# N32H7xx register map
Vendor: Nationstech Ltd.; File version: 1.0
CPU: CM7 r1p1, little endian, MPU, FPU, 4 interrupt priority bits
Registers are 32-bit, read-write, reset 0x0 unless marked. A register's access mark holds for its fields unless they carry their own. Offsets are from the block's base; [hi:lo] are bit positions; {n}, {i} and the like mark numbered series.

## RCC — Reset and clock control
Base 0x58030000
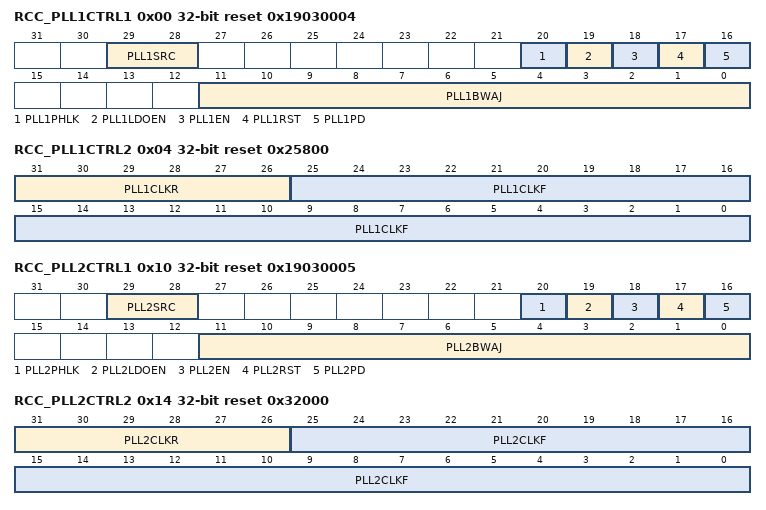
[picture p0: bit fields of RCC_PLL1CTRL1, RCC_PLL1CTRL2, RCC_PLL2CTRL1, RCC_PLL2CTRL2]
0x00 RCC_PLL1CTRL1 reset 0x19030004 — nan
  [29:28] PLL1SRC, [20] PLL1PHLK ro, [19] PLL1LDOEN, [18] PLL1EN, [17] PLL1RST, [16] PLL1PD, [11:0] PLL1BWAJ
0x04 RCC_PLL1CTRL2 reset 0x25800 — nan
  [31:26] PLL1CLKR, [25:0] PLL1CLKF
0x10 RCC_PLL2CTRL1 reset 0x19030005 — nan
  [29:28] PLL2SRC, [20] PLL2PHLK ro, [19] PLL2LDOEN, [18] PLL2EN, [17] PLL2RST, [16] PLL2PD, [11:0] PLL2BWAJ
0x14 RCC_PLL2CTRL2 reset 0x32000 — nan
  [31:26] PLL2CLKR, [25:0] PLL2CLKF
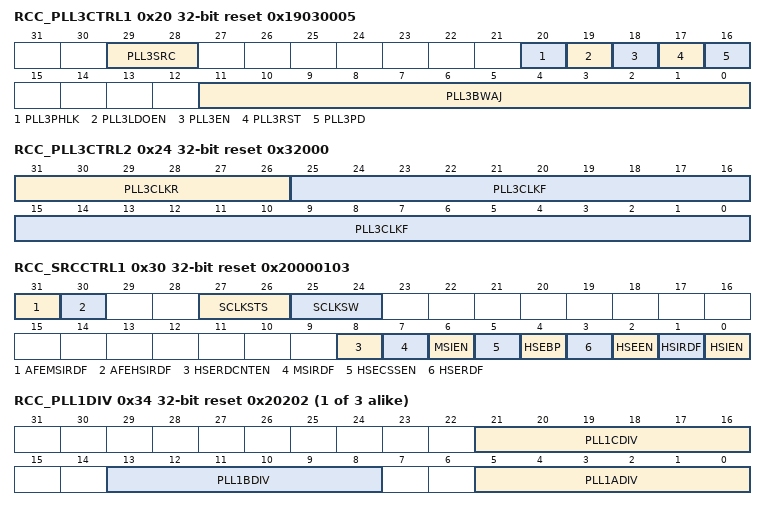
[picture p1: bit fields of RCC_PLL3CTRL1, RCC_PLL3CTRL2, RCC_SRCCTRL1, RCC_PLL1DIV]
0x20 RCC_PLL3CTRL1 reset 0x19030005 — nan
  [29:28] PLL3SRC, [20] PLL3PHLK ro, [19] PLL3LDOEN, [18] PLL3EN, [17] PLL3RST, [16] PLL3PD, [11:0] PLL3BWAJ
0x24 RCC_PLL3CTRL2 reset 0x32000 — nan
  [31:26] PLL3CLKR, [25:0] PLL3CLKF
0x30 RCC_SRCCTRL1 reset 0x20000103 — nan
  [31] AFEMSIRDF ro, [30] AFEHSIRDF ro, [27:26] SCLKSTS ro, [25:24] SCLKSW, [8] HSERDCNTEN, [7] MSIRDF ro, [6] MSIEN, [5] HSECSSEN, [4] HSEBP, [3] HSERDF ro, [2] HSEEN, [1] HSIRDF ro, [0] HSIEN
{0x30+4i} RCC_PLL{i}DIV reset 0x20202 (i=1..3) — nan
  [21:16] PLL{i}CDIV, [13:8] PLL{i}BDIV, [5:0] PLL{i}ADIV
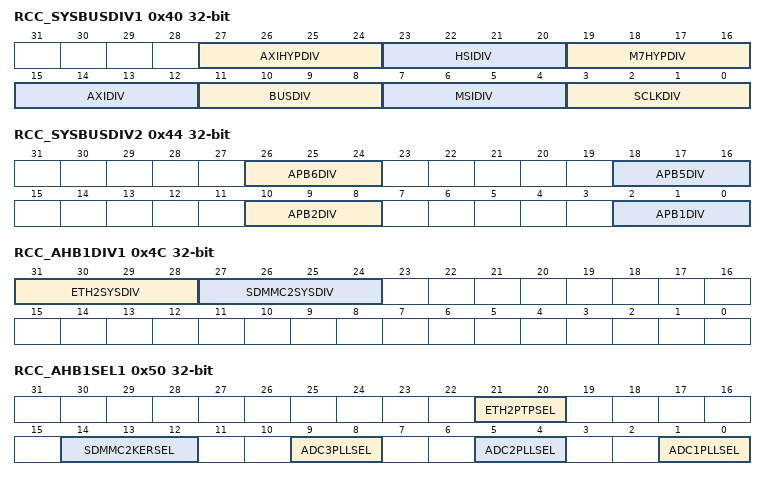
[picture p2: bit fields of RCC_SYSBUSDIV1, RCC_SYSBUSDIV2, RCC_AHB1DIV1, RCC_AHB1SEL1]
0x40 RCC_SYSBUSDIV1 — nan
  [27:24] AXIHYPDIV, [23:20] HSIDIV, [19:16] M7HYPDIV, [15:12] AXIDIV, [11:8] BUSDIV, [7:4] MSIDIV, [3:0] SCLKDIV
0x44 RCC_SYSBUSDIV2 — nan
  [26:24] APB6DIV, [18:16] APB5DIV, [10:8] APB2DIV, [2:0] APB1DIV
0x48 RCC_BOOTMODE — nan
  [31:0] MODE
0x4C RCC_AHB1DIV1 — nan
  [31:28] ETH2SYSDIV, [27:24] SDMMC2SYSDIV
0x50 RCC_AHB1SEL1 — nan
  [21:20] ETH2PTPSEL, [14:12] SDMMC2KERSEL, [9:8] ADC3PLLSEL, [5:4] ADC2PLLSEL, [1:0] ADC1PLLSEL
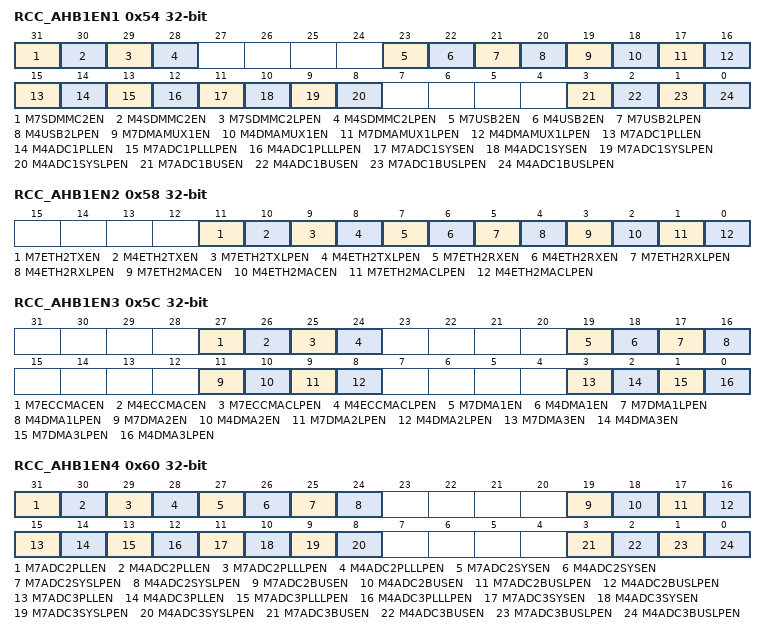
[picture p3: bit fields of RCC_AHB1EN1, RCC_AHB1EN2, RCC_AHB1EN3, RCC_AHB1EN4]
0x54 RCC_AHB1EN1 — nan
  [31] M7SDMMC2EN, [30] M4SDMMC2EN, [29] M7SDMMC2LPEN, [28] M4SDMMC2LPEN, [23] M7USB2EN, [22] M4USB2EN, [21] M7USB2LPEN, [20] M4USB2LPEN, [19] M7DMAMUX1EN, [18] M4DMAMUX1EN, [17] M7DMAMUX1LPEN, [16] M4DMAMUX1LPEN, [15] M7ADC1PLLEN, [14] M4ADC1PLLEN, [13] M7ADC1PLLLPEN, [12] M4ADC1PLLLPEN, [11] M7ADC1SYSEN, [10] M4ADC1SYSEN, [9] M7ADC1SYSLPEN, [8] M4ADC1SYSLPEN, [3] M7ADC1BUSEN, [2] M4ADC1BUSEN, [1] M7ADC1BUSLPEN, [0] M4ADC1BUSLPEN
0x58 RCC_AHB1EN2 — nan
  [11] M7ETH2TXEN, [10] M4ETH2TXEN, [9] M7ETH2TXLPEN, [8] M4ETH2TXLPEN, [7] M7ETH2RXEN, [6] M4ETH2RXEN, [5] M7ETH2RXLPEN, [4] M4ETH2RXLPEN, [3] M7ETH2MACEN, [2] M4ETH2MACEN, [1] M7ETH2MACLPEN, [0] M4ETH2MACLPEN
0x5C RCC_AHB1EN3 — nan
  [27] M7ECCMACEN, [26] M4ECCMACEN, [25] M7ECCMACLPEN, [24] M4ECCMACLPEN, [19] M7DMA1EN, [18] M4DMA1EN, [17] M7DMA1LPEN, [16] M4DMA1LPEN, [11] M7DMA2EN, [10] M4DMA2EN, [9] M7DMA2LPEN, [8] M4DMA2LPEN, [3] M7DMA3EN, [2] M4DMA3EN, [1] M7DMA3LPEN, [0] M4DMA3LPEN
0x60 RCC_AHB1EN4 — nan
  [31] M7ADC2PLLEN, [30] M4ADC2PLLEN, [29] M7ADC2PLLLPEN, [28] M4ADC2PLLLPEN, [27] M7ADC2SYSEN, [26] M4ADC2SYSEN, [25] M7ADC2SYSLPEN, [24] M4ADC2SYSLPEN, [19] M7ADC2BUSEN, [18] M4ADC2BUSEN, [17] M7ADC2BUSLPEN, [16] M4ADC2BUSLPEN, [15] M7ADC3PLLEN, [14] M4ADC3PLLEN, [13] M7ADC3PLLLPEN, [12] M4ADC3PLLLPEN, [11] M7ADC3SYSEN, [10] M4ADC3SYSEN, [9] M7ADC3SYSLPEN, [8] M4ADC3SYSLPEN, [3] M7ADC3BUSEN, [2] M4ADC3BUSEN, [1] M7ADC3BUSLPEN, [0] M4ADC3BUSLPEN
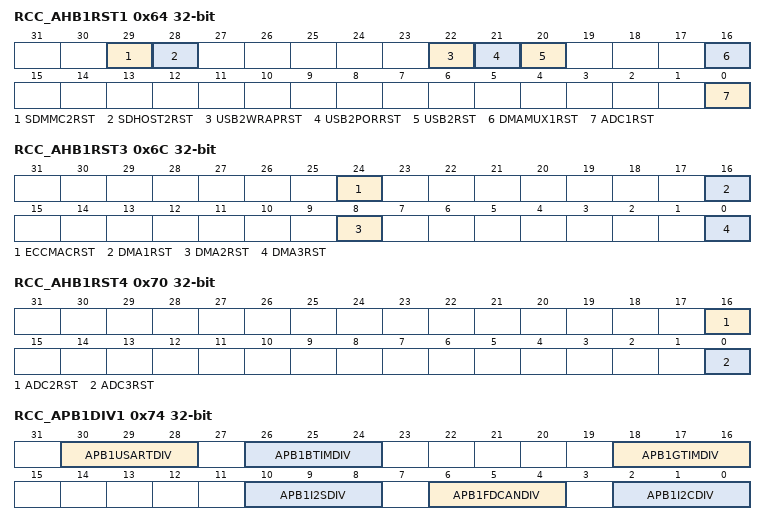
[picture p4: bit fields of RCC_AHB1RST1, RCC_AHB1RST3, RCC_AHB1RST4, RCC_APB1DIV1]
0x64 RCC_AHB1RST1 — nan
  [29] SDMMC2RST, [28] SDHOST2RST, [22] USB2WRAPRST, [21] USB2PORRST, [20] USB2RST, [16] DMAMUX1RST, [0] ADC1RST
0x68 RCC_AHB1RST2 — nan
  [0] ETH2RST
0x6C RCC_AHB1RST3 — nan
  [24] ECCMACRST, [16] DMA1RST, [8] DMA2RST, [0] DMA3RST
0x70 RCC_AHB1RST4 — nan
  [16] ADC2RST, [0] ADC3RST
0x74 RCC_APB1DIV1 — nan
  [30:28] APB1USARTDIV, [26:24] APB1BTIMDIV, [18:16] APB1GTIMDIV, [10:8] APB1I2SDIV, [6:4] APB1FDCANDIV, [2:0] APB1I2CDIV
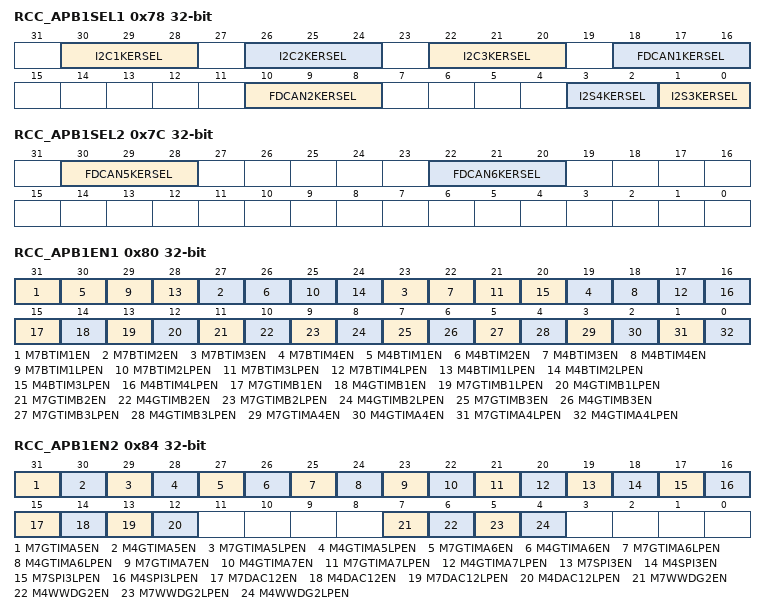
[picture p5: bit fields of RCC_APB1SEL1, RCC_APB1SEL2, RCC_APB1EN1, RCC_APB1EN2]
0x78 RCC_APB1SEL1 — nan
  [30:28] I2C1KERSEL, [26:24] I2C2KERSEL, [22:20] I2C3KERSEL, [18:16] FDCAN1KERSEL, [10:8] FDCAN2KERSEL, [3:2] I2S4KERSEL, [1:0] I2S3KERSEL
0x7C RCC_APB1SEL2 — nan
  [30:28] FDCAN5KERSEL, [22:20] FDCAN6KERSEL
0x80 RCC_APB1EN1 — nan
  [35-4n] M7BTIM{n}EN (n=1..4), [34-4n] M4BTIM{n}EN (n=1..4), [33-4n] M7BTIM{n}LPEN (n=1..4), [32-4n] M4BTIM{n}LPEN (n=1..4), [15] M7GTIMB1EN, [14] M4GTIMB1EN, [13] M7GTIMB1LPEN, [12] M4GTIMB1LPEN, [11] M7GTIMB2EN, [10] M4GTIMB2EN, [9] M7GTIMB2LPEN, [8] M4GTIMB2LPEN, [7] M7GTIMB3EN, [6] M4GTIMB3EN, [5] M7GTIMB3LPEN, [4] M4GTIMB3LPEN, [3] M7GTIMA4EN, [2] M4GTIMA4EN, [1] M7GTIMA4LPEN, [0] M4GTIMA4LPEN
0x84 RCC_APB1EN2 — nan
  [31] M7GTIMA5EN, [30] M4GTIMA5EN, [29] M7GTIMA5LPEN, [28] M4GTIMA5LPEN, [27] M7GTIMA6EN, [26] M4GTIMA6EN, [25] M7GTIMA6LPEN, [24] M4GTIMA6LPEN, [23] M7GTIMA7EN, [22] M4GTIMA7EN, [21] M7GTIMA7LPEN, [20] M4GTIMA7LPEN, [19] M7SPI3EN, [18] M4SPI3EN, [17] M7SPI3LPEN, [16] M4SPI3LPEN, [15] M7DAC12EN, [14] M4DAC12EN, [13] M7DAC12LPEN, [12] M4DAC12LPEN, [7] M7WWDG2EN, [6] M4WWDG2EN, [5] M7WWDG2LPEN, [4] M4WWDG2LPEN
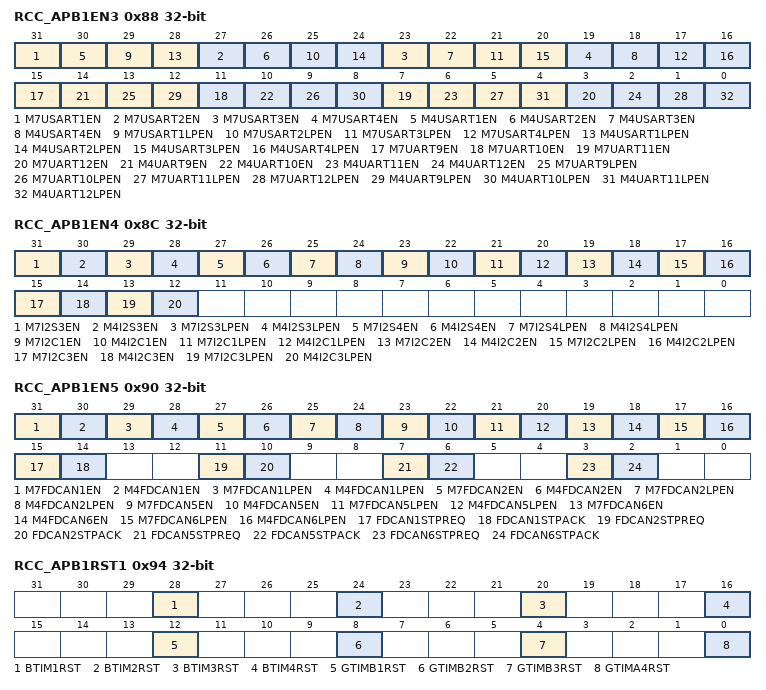
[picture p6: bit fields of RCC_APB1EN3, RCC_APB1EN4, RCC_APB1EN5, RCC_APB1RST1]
0x88 RCC_APB1EN3 — nan
  [35-4n] M7USART{n}EN (n=1..4), [34-4n] M4USART{n}EN (n=1..4), [33-4n] M7USART{n}LPEN (n=1..4), [32-4n] M4USART{n}LPEN (n=1..4), [51-4n] M7UART{n}EN (n=9..12), [50-4n] M4UART{n}EN (n=9..12), [49-4n] M7UART{n}LPEN (n=9..12), [48-4n] M4UART{n}LPEN (n=9..12)
0x8C RCC_APB1EN4 — nan
  [31] M7I2S3EN, [30] M4I2S3EN, [29] M7I2S3LPEN, [28] M4I2S3LPEN, [27] M7I2S4EN, [26] M4I2S4EN, [25] M7I2S4LPEN, [24] M4I2S4LPEN, [23] M7I2C1EN, [22] M4I2C1EN, [21] M7I2C1LPEN, [20] M4I2C1LPEN, [19] M7I2C2EN, [18] M4I2C2EN, [17] M7I2C2LPEN, [16] M4I2C2LPEN, [15] M7I2C3EN, [14] M4I2C3EN, [13] M7I2C3LPEN, [12] M4I2C3LPEN
0x90 RCC_APB1EN5 — nan
  [31] M7FDCAN1EN, [30] M4FDCAN1EN, [29] M7FDCAN1LPEN, [28] M4FDCAN1LPEN, [27] M7FDCAN2EN, [26] M4FDCAN2EN, [25] M7FDCAN2LPEN, [24] M4FDCAN2LPEN, [23] M7FDCAN5EN, [22] M4FDCAN5EN, [21] M7FDCAN5LPEN, [20] M4FDCAN5LPEN, [19] M7FDCAN6EN, [18] M4FDCAN6EN, [17] M7FDCAN6LPEN, [16] M4FDCAN6LPEN, [15] FDCAN1STPREQ, [14] FDCAN1STPACK ro, [11] FDCAN2STPREQ, [10] FDCAN2STPACK ro, [7] FDCAN5STPREQ, [6] FDCAN5STPACK ro, [3] FDCAN6STPREQ, [2] FDCAN6STPACK ro
0x94 RCC_APB1RST1 — nan
  [32-4n] BTIM{n}RST (n=1..4), [12] GTIMB1RST, [8] GTIMB2RST, [4] GTIMB3RST, [0] GTIMA4RST
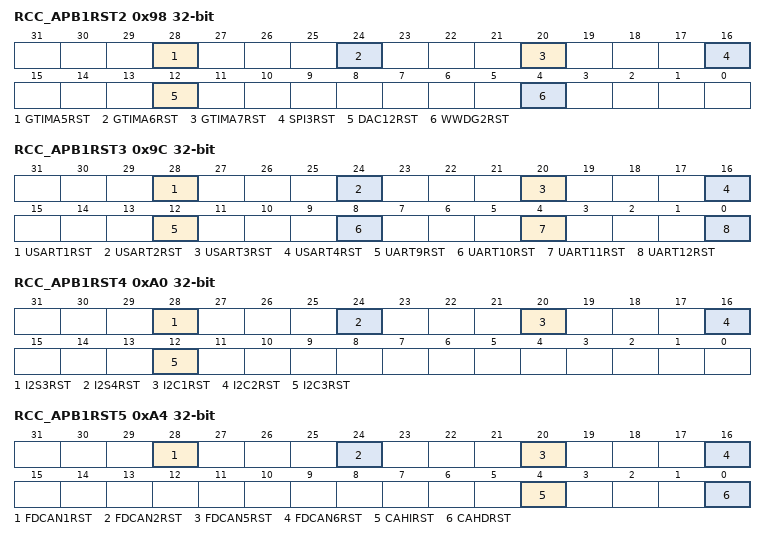
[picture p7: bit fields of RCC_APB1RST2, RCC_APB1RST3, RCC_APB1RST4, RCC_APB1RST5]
0x98 RCC_APB1RST2 — nan
  [28] GTIMA5RST, [24] GTIMA6RST, [20] GTIMA7RST, [16] SPI3RST, [12] DAC12RST, [4] WWDG2RST
0x9C RCC_APB1RST3 — nan
  [32-4n] USART{n}RST (n=1..4), [48-4n] UART{n}RST (n=9..12)
0xA0 RCC_APB1RST4 — nan
  [28] I2S3RST, [24] I2S4RST, [20] I2C1RST, [16] I2C2RST, [12] I2C3RST
0xA4 RCC_APB1RST5 — nan
  [28] FDCAN1RST, [24] FDCAN2RST, [20] FDCAN5RST, [16] FDCAN6RST, [4] CAHIRST, [0] CAHDRST
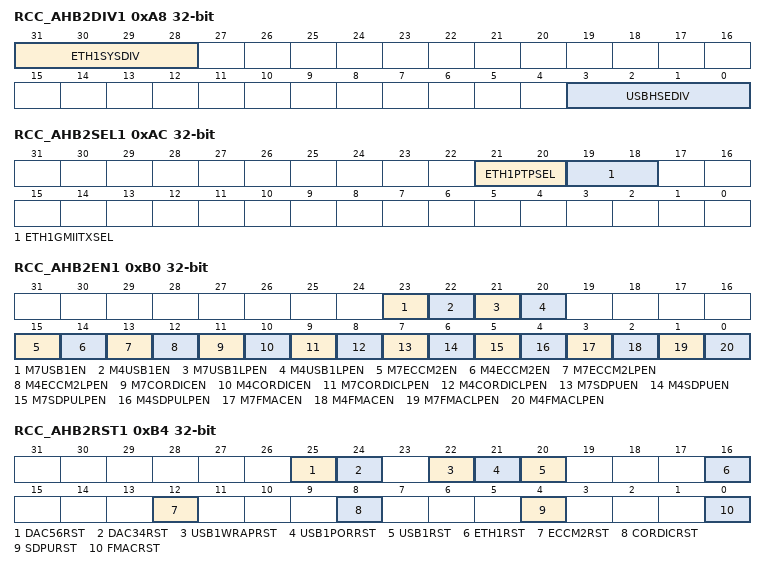
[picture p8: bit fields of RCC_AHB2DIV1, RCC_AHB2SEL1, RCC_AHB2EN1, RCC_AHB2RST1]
0xA8 RCC_AHB2DIV1 — nan
  [31:28] ETH1SYSDIV, [3:0] USBHSEDIV
0xAC RCC_AHB2SEL1 — nan
  [21:20] ETH1PTPSEL, [19:18] ETH1GMIITXSEL
0xB0 RCC_AHB2EN1 — nan
  [23] M7USB1EN, [22] M4USB1EN, [21] M7USB1LPEN, [20] M4USB1LPEN, [15] M7ECCM2EN, [14] M4ECCM2EN, [13] M7ECCM2LPEN, [12] M4ECCM2LPEN, [11] M7CORDICEN, [10] M4CORDICEN, [9] M7CORDICLPEN, [8] M4CORDICLPEN, [7] M7SDPUEN, [6] M4SDPUEN, [5] M7SDPULPEN, [4] M4SDPULPEN, [3] M7FMACEN, [2] M4FMACEN, [1] M7FMACLPEN, [0] M4FMACLPEN
0xB4 RCC_AHB2RST1 — nan
  [25] DAC56RST, [24] DAC34RST, [22] USB1WRAPRST, [21] USB1PORRST, [20] USB1RST, [16] ETH1RST, [12] ECCM2RST, [8] CORDICRST, [4] SDPURST, [0] FMACRST
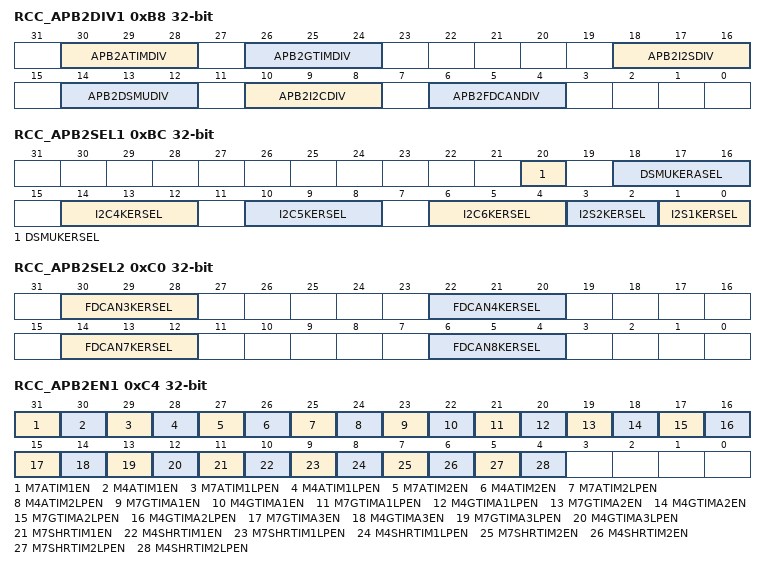
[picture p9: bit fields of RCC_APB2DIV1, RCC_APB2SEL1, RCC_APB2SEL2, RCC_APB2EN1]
0xB8 RCC_APB2DIV1 — nan
  [30:28] APB2ATIMDIV, [26:24] APB2GTIMDIV, [18:16] APB2I2SDIV, [14:12] APB2DSMUDIV, [10:8] APB2I2CDIV, [6:4] APB2FDCANDIV
0xBC RCC_APB2SEL1 — nan
  [20] DSMUKERSEL, [18:16] DSMUKERASEL, [14:12] I2C4KERSEL, [10:8] I2C5KERSEL, [6:4] I2C6KERSEL, [3:2] I2S2KERSEL, [1:0] I2S1KERSEL
0xC0 RCC_APB2SEL2 — nan
  [30:28] FDCAN3KERSEL, [22:20] FDCAN4KERSEL, [14:12] FDCAN7KERSEL, [6:4] FDCAN8KERSEL
0xC4 RCC_APB2EN1 — nan
  [31] M7ATIM1EN, [30] M4ATIM1EN, [29] M7ATIM1LPEN, [28] M4ATIM1LPEN, [27] M7ATIM2EN, [26] M4ATIM2EN, [25] M7ATIM2LPEN, [24] M4ATIM2LPEN, [23] M7GTIMA1EN, [22] M4GTIMA1EN, [21] M7GTIMA1LPEN, [20] M4GTIMA1LPEN, [19] M7GTIMA2EN, [18] M4GTIMA2EN, [17] M7GTIMA2LPEN, [16] M4GTIMA2LPEN, [15] M7GTIMA3EN, [14] M4GTIMA3EN, [13] M7GTIMA3LPEN, [12] M4GTIMA3LPEN, [11] M7SHRTIM1EN, [10] M4SHRTIM1EN, [9] M7SHRTIM1LPEN, [8] M4SHRTIM1LPEN, [7] M7SHRTIM2EN, [6] M4SHRTIM2EN, [5] M7SHRTIM2LPEN, [4] M4SHRTIM2LPEN
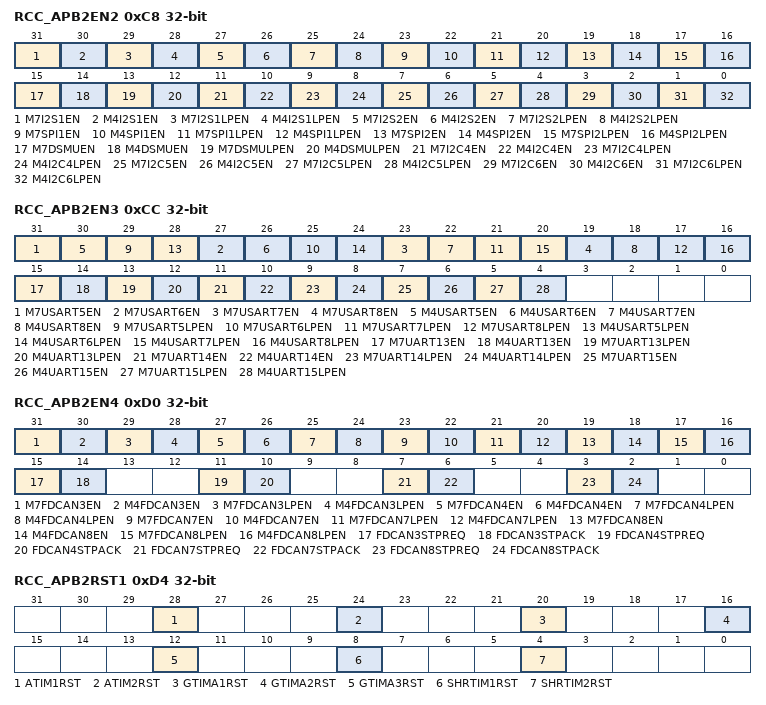
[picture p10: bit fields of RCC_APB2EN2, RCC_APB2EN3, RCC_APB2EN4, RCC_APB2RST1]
0xC8 RCC_APB2EN2 — nan
  [31] M7I2S1EN, [30] M4I2S1EN, [29] M7I2S1LPEN, [28] M4I2S1LPEN, [27] M7I2S2EN, [26] M4I2S2EN, [25] M7I2S2LPEN, [24] M4I2S2LPEN, [23] M7SPI1EN, [22] M4SPI1EN, [21] M7SPI1LPEN, [20] M4SPI1LPEN, [19] M7SPI2EN, [18] M4SPI2EN, [17] M7SPI2LPEN, [16] M4SPI2LPEN, [15] M7DSMUEN, [14] M4DSMUEN, [13] M7DSMULPEN, [12] M4DSMULPEN, [11] M7I2C4EN, [10] M4I2C4EN, [9] M7I2C4LPEN, [8] M4I2C4LPEN, [7] M7I2C5EN, [6] M4I2C5EN, [5] M7I2C5LPEN, [4] M4I2C5LPEN, [3] M7I2C6EN, [2] M4I2C6EN, [1] M7I2C6LPEN, [0] M4I2C6LPEN
0xCC RCC_APB2EN3 — nan
  [51-4n] M7USART{n}EN (n=5..8), [50-4n] M4USART{n}EN (n=5..8), [49-4n] M7USART{n}LPEN (n=5..8), [48-4n] M4USART{n}LPEN (n=5..8), [15] M7UART13EN, [14] M4UART13EN, [13] M7UART13LPEN, [12] M4UART13LPEN, [11] M7UART14EN, [10] M4UART14EN, [9] M7UART14LPEN, [8] M4UART14LPEN, [7] M7UART15EN, [6] M4UART15EN, [5] M7UART15LPEN, [4] M4UART15LPEN
0xD0 RCC_APB2EN4 — nan
  [31] M7FDCAN3EN, [30] M4FDCAN3EN, [29] M7FDCAN3LPEN, [28] M4FDCAN3LPEN, [27] M7FDCAN4EN, [26] M4FDCAN4EN, [25] M7FDCAN4LPEN, [24] M4FDCAN4LPEN, [23] M7FDCAN7EN, [22] M4FDCAN7EN, [21] M7FDCAN7LPEN, [20] M4FDCAN7LPEN, [19] M7FDCAN8EN, [18] M4FDCAN8EN, [17] M7FDCAN8LPEN, [16] M4FDCAN8LPEN, [15] FDCAN3STPREQ, [14] FDCAN3STPACK ro, [11] FDCAN4STPREQ, [10] FDCAN4STPACK ro, [7] FDCAN7STPREQ, [6] FDCAN7STPACK ro, [3] FDCAN8STPREQ, [2] FDCAN8STPACK ro
0xD4 RCC_APB2RST1 — nan
  [28] ATIM1RST, [24] ATIM2RST, [20] GTIMA1RST, [16] GTIMA2RST, [12] GTIMA3RST, [8] SHRTIM1RST, [4] SHRTIM2RST
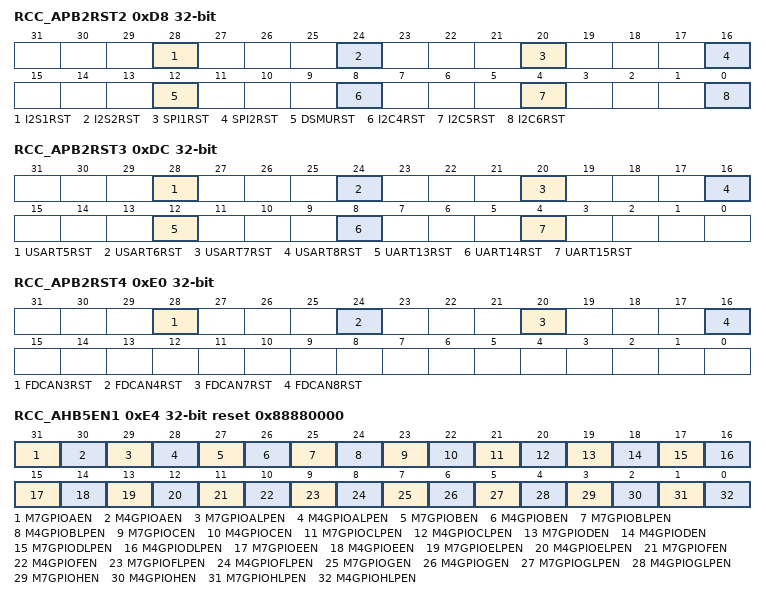
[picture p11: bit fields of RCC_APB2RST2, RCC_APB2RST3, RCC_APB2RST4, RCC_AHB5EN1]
0xD8 RCC_APB2RST2 — nan
  [28] I2S1RST, [24] I2S2RST, [20] SPI1RST, [16] SPI2RST, [12] DSMURST, [8] I2C4RST, [4] I2C5RST, [0] I2C6RST
0xDC RCC_APB2RST3 — nan
  [48-4n] USART{n}RST (n=5..8), [12] UART13RST, [8] UART14RST, [4] UART15RST
0xE0 RCC_APB2RST4 — nan
  [28] FDCAN3RST, [24] FDCAN4RST, [20] FDCAN7RST, [16] FDCAN8RST
0xE4 RCC_AHB5EN1 reset 0x88880000 — nan
  [31] M7GPIOAEN, [30] M4GPIOAEN, [29] M7GPIOALPEN, [28] M4GPIOALPEN, [27] M7GPIOBEN, [26] M4GPIOBEN, [25] M7GPIOBLPEN, [24] M4GPIOBLPEN, [23] M7GPIOCEN, [22] M4GPIOCEN, [21] M7GPIOCLPEN, [20] M4GPIOCLPEN, [19] M7GPIODEN, [18] M4GPIODEN, [17] M7GPIODLPEN, [16] M4GPIODLPEN, [15] M7GPIOEEN, [14] M4GPIOEEN, [13] M7GPIOELPEN, [12] M4GPIOELPEN, [11] M7GPIOFEN, [10] M4GPIOFEN, [9] M7GPIOFLPEN, [8] M4GPIOFLPEN, [7] M7GPIOGEN, [6] M4GPIOGEN, [5] M7GPIOGLPEN, [4] M4GPIOGLPEN, [3] M7GPIOHEN, [2] M4GPIOHEN, [1] M7GPIOHLPEN, [0] M4GPIOHLPEN
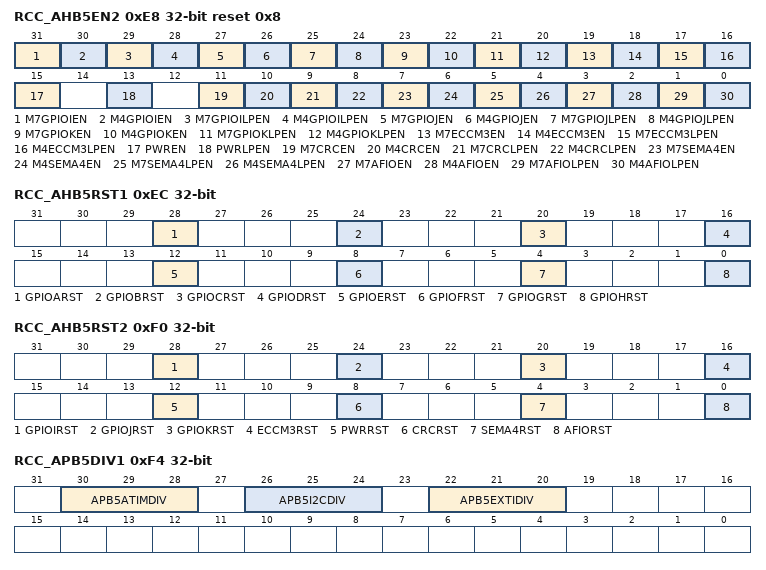
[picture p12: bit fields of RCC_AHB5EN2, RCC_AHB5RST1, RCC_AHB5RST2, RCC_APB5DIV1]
0xE8 RCC_AHB5EN2 reset 0x8 — nan
  [31] M7GPIOIEN, [30] M4GPIOIEN, [29] M7GPIOILPEN, [28] M4GPIOILPEN, [27] M7GPIOJEN, [26] M4GPIOJEN, [25] M7GPIOJLPEN, [24] M4GPIOJLPEN, [23] M7GPIOKEN, [22] M4GPIOKEN, [21] M7GPIOKLPEN, [20] M4GPIOKLPEN, [19] M7ECCM3EN, [18] M4ECCM3EN, [17] M7ECCM3LPEN, [16] M4ECCM3LPEN, [15] PWREN, [13] PWRLPEN, [11] M7CRCEN, [10] M4CRCEN, [9] M7CRCLPEN, [8] M4CRCLPEN, [7] M7SEMA4EN, [6] M4SEMA4EN, [5] M7SEMA4LPEN, [4] M4SEMA4LPEN, [3] M7AFIOEN, [2] M4AFIOEN, [1] M7AFIOLPEN, [0] M4AFIOLPEN
0xEC RCC_AHB5RST1 — nan
  [28] GPIOARST, [24] GPIOBRST, [20] GPIOCRST, [16] GPIODRST, [12] GPIOERST, [8] GPIOFRST, [4] GPIOGRST, [0] GPIOHRST
0xF0 RCC_AHB5RST2 — nan
  [28] GPIOIRST, [24] GPIOJRST, [20] GPIOKRST, [16] ECCM3RST, [12] PWRRST, [8] CRCRST, [4] SEMA4RST, [0] AFIORST
0xF4 RCC_APB5DIV1 — nan
  [30:28] APB5ATIMDIV, [26:24] APB5I2CDIV, [22:20] APB5EXTIDIV
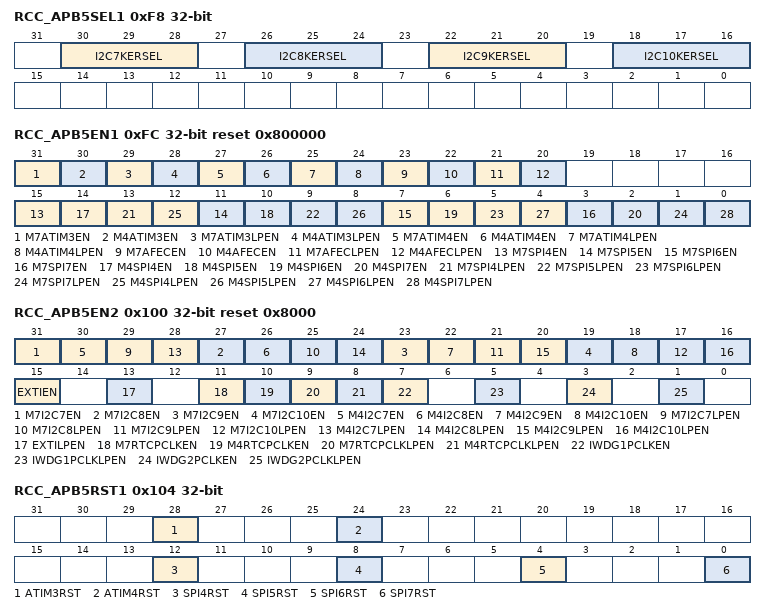
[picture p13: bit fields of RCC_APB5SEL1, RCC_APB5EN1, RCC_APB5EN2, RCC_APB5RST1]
0xF8 RCC_APB5SEL1 — nan
  [58-4n:56-4n] I2C{n}KERSEL (n=7..10)
0xFC RCC_APB5EN1 reset 0x800000 — nan
  [31] M7ATIM3EN, [30] M4ATIM3EN, [29] M7ATIM3LPEN, [28] M4ATIM3LPEN, [27] M7ATIM4EN, [26] M4ATIM4EN, [25] M7ATIM4LPEN, [24] M4ATIM4LPEN, [23] M7AFECEN, [22] M4AFECEN, [21] M7AFECLPEN, [20] M4AFECLPEN, [31-4n] M7SPI{n}EN (n=4..7), [30-4n] M4SPI{n}EN (n=4..7), [29-4n] M7SPI{n}LPEN (n=4..7), [28-4n] M4SPI{n}LPEN (n=4..7)
0x100 RCC_APB5EN2 reset 0x8000 — nan
  [59-4n] M7I2C{n}EN (n=7..10), [58-4n] M4I2C{n}EN (n=7..10), [57-4n] M7I2C{n}LPEN (n=7..10), [56-4n] M4I2C{n}LPEN (n=7..10), [15] EXTIEN, [13] EXTILPEN, [11] M7RTCPCLKEN, [10] M4RTCPCLKEN, [9] M7RTCPCLKLPEN, [8] M4RTCPCLKLPEN, [7] IWDG1PCLKEN, [5] IWDG1PCLKLPEN, [3] IWDG2PCLKEN, [1] IWDG2PCLKLPEN
0x104 RCC_APB5RST1 — nan
  [28] ATIM3RST, [24] ATIM4RST, [28-4n] SPI{n}RST (n=4..7)
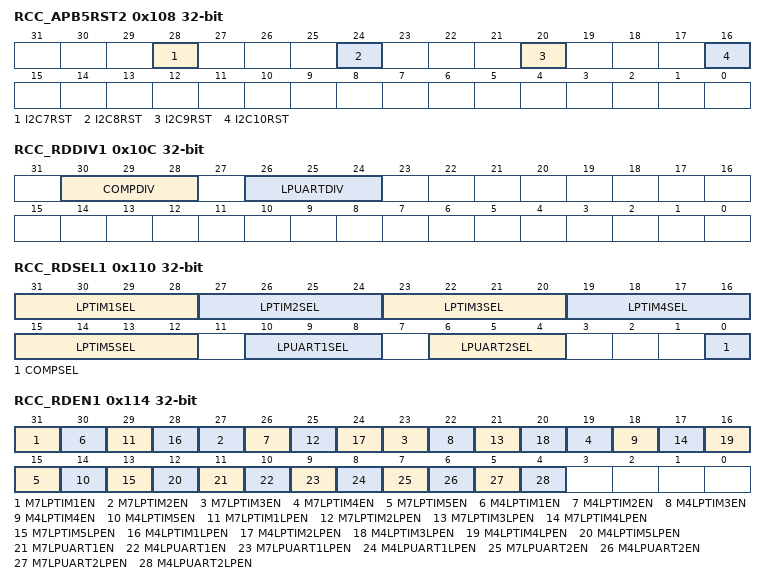
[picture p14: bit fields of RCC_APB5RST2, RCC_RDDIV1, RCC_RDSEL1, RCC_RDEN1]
0x108 RCC_APB5RST2 — nan
  [56-4n] I2C{n}RST (n=7..10)
0x10C RCC_RDDIV1 — nan
  [30:28] COMPDIV, [26:24] LPUARTDIV
0x110 RCC_RDSEL1 — nan
  [35-4n:32-4n] LPTIM{n}SEL (n=1..5), [10:8] LPUART1SEL, [6:4] LPUART2SEL, [0] COMPSEL
0x114 RCC_RDEN1 — nan
  [35-4n] M7LPTIM{n}EN (n=1..5), [34-4n] M4LPTIM{n}EN (n=1..5), [33-4n] M7LPTIM{n}LPEN (n=1..5), [32-4n] M4LPTIM{n}LPEN (n=1..5), [11] M7LPUART1EN, [10] M4LPUART1EN, [9] M7LPUART1LPEN, [8] M4LPUART1LPEN, [7] M7LPUART2EN, [6] M4LPUART2EN, [5] M7LPUART2LPEN, [4] M4LPUART2LPEN
0x118 RCC_RDEN2 — nan
  [31] M7COMPEN, [30] M4COMPEN, [29] M7COMPLPEN, [28] M4COMPLPEN
0x11C RCC_RDRST1 — nan
  [32-4n] LPTIM{n}RST (n=1..5), [8] LPUART1RST, [4] LPUART2RST
0x120 RCC_RDRST2 — nan
  [28] COMPRST
0x124 RCC_BDCTRL reset 0x148EC0F — nan
  [31] AFELSERDF ro, [30] AFELSIRDF ro, [28] LSELDOEN, [27] LSIOVREN, [26] LSIPFACK, [25] LSIPFF ro, [24] LSICSSEN, [22] LSERDCNTEN, [21] RTCLSFSW ro, [20] RTCHSFSW ro, [19] LSISECRDF ro, [18] RTCEN, [17:16] RTCSEL, [15] BORRSTEN, [14] C1LPRSTEN, [13] C2LPRSTEN, [12] BDRST, [11] BKPEMCRSTEN, [10] RETEMCRSTEN, [9] LSECSSF ro, [8] LSECSSEN, [7] LSERDEN, [6] LSEBP, [5] LSERDF ro, [4] LSEEN, [3] LSIRDEN, [2] LSISECEN, [1] LSIRDF ro, [0] LSIEN
0x128 RCC_CTRLSTS reset 0x3 — nan
  [31] RMRSTF, [15] C1LPRSTF ro, [14] C2LPRSTF ro, [13] RETEMCRSTF ro, [12] BKPEMCRSTF ro, [11] BORRSTF ro, [9] MMURSTF ro, [7] WWDG1RSTF ro, [6] WWDG2RSTF ro, [5] IWDG1RSTF ro, [4] IWDG2RSTF ro, [3] CM4SFTRSTF ro, [2] CM7SFTRSTF ro, [1] PORRSTF ro, [0] PINRSTF ro
0x12C RCC_CLKINT1 — nan
  [30] LSECSSIE, [29] LSECSSIF ro, [28] LSECSSIC wo, [25] HSECSSIF ro, [24] HSECSSIC wo, [22] BORIE, [21] BORIF ro, [20] BORIC wo, [18] PLL1RDIE, [17] PLL1RDIF ro, [16] PLL1RDIC wo, [14] PLL2RDIE, [13] PLL2RDIF ro, [12] PLL2RDIC wo, [10] PLL3RDIE, [9] PLL3RDIF ro, [8] PLL3RDIC wo, [6] SHRPLLRDIE, [5] SHRPLLRDIF ro, [4] SHRPLLRDIC wo
0x130 RCC_CLKINT2 — nan
  [30] HSERDIE, [29] HSERDIF ro, [28] HSERDIC wo, [26] HSIRDIE, [25] HSIRDIF ro, [24] HSIRDIC wo, [22] MSIRDIE, [21] MSIRDIF ro, [20] MSIRDIC wo, [18] LSERDIE, [17] LSERDIF ro, [16] LSERDIC wo, [14] LSIRDIE, [13] LSIRDIF ro, [12] LSIRDIC wo, [10] HSICALEIE, [9] HSICALEIF ro, [8] HSICALEIC wo, [6] MSICALEIE, [5] MSICALEIF ro, [4] MSICALEIC wo
0x134 RCC_CFG1 reset 0xAA0000 — nan
  [23:20] WWDG2RSTDLCNT, [19:16] WWDG1RSTDLCNT, [9] WWDG2RSTEN, [8] WWDG1RSTEN, [7:4] M7TRACEDIV, [3:0] M4TRACEDIV
0x138 RCC_AXIDIV1 — nan
  [23:20] SDMMC1AXIDIV, [19:16] DSIREFDIV, [15:12] LCDCAXIDIV, [11:8] DVPMAXIDIV
0x13C RCC_AXISEL1 — nan
  [27:26] DSIULPSSEL, [25:24] DSIKERSEL, [22:20] SDMMC1KERSEL, [17:16] DSIPPITXSEL, [13:12] LCDCKERSEL, [11:10] DVP1MSEL, [9:8] DVP2MSEL, [6:4] XSPI1SSISEL, [2:0] XSPI2SSISEL
0x140 RCC_AXIEN1 — nan
  [31] M7JPEGDEN, [30] M4JPEGDEN, [29] M7JPEGDLPEN, [28] M4JPEGDLPEN, [23] M7JPEGEEN, [22] M4JPEGEEN, [21] M7JPEGELPEN, [20] M4JPEGELPEN, [19] M7DMAMUX2EN, [18] M4DMAMUX2EN, [17] M7DMAMUX2LPEN, [16] M4DMAMUX2LPEN, [15] M7MDMAEN, [14] M4MDMAEN, [13] M7MDMALPEN, [12] M4MDMALPEN, [11] M7SDMMC1EN, [10] M4SDMMC1EN, [9] M7SDMMC1LPEN, [8] M4SDMMC1LPEN, [7] M7ECCM1EN, [6] M4ECCM1EN, [5] M7ECCM1LPEN, [4] M4ECCM1LPEN, [3] M7OTPCEN, [2] M4OTPCEN, [1] M7OTPCLPEN, [0] M4OTPCLPEN
0x144 RCC_AXIEN2 — nan
  [31] M7DSIEN, [30] M4DSIEN, [29] M7DSILPEN, [28] M4DSILPEN, [27] M7LCDCEN, [26] M4LCDCEN, [25] M7LCDCLPEN, [24] M4LCDCLPEN, [23] M7LCDCAPBEN, [22] M4LCDCAPBEN, [21] M7LCDCAPBLPEN, [20] M4LCDCAPBLPEN, [19] M7DVP1EN, [18] M4DVP1EN, [17] M7DVP1LPEN, [16] M4DVP1LPEN, [15] M7DVP1APBEN, [14] M4DVP1APBEN, [13] M7DVP1APBLPEN, [12] M4DVP1APBLPEN, [11] M7DVP2EN, [10] M4DVP2EN, [9] M7DVP2LPEN, [8] M4DVP2LPEN, [7] M7DVP2APBEN, [6] M4DVP2APBEN, [5] M7DVP2APBLPEN, [4] M4DVP2APBLPEN, [3] M7WWDG1EN, [2] M4WWDG1EN, [1] M7WWDG1LPEN, [0] M4WWDG1LPEN
0x148 RCC_AXIEN3 reset 0x88888880 — nan
  [31] M7TASRAM2EN, [30] M4TASRAM2EN, [29] M7TASRAM2LPEN, [28] M4TASRAM2LPEN, [27] M7TASRAM3EN, [26] M4TASRAM3EN, [25] M7TASRAM3LPEN, [24] M4TASRAM3LPEN, [23] M7TCMEN, [22] M4TCMEN, [21] M7TCMLPEN, [20] M4TCMLPEN, [19] M7TCMAXIEN, [18] M4TCMAXIEN, [17] M7TCMAXILPEN, [16] M4TCMAXILPEN, [15] M7TCMAPBEN, [14] M4TCMAPBEN, [13] M7TCMAPBLPEN, [12] M4TCMAPBLPEN, [11] M7ASRAM1EN, [10] M4ASRAM1EN, [9] M7ASRAM1LPEN, [8] M4ASRAM1LPEN, [7] M7AXIROMEN, [6] M4AXIROMEN, [5] M7AXIROMLPEN, [4] M4AXIROMLPEN, [3] M7GPUEN, [2] M4GPUEN, [1] M7GPULPEN, [0] M4GPULPEN
0x14C RCC_AXIEN4 reset 0x880000 — nan
  [31] M7XSPI1EN, [30] M4XSPI1EN, [29] M7XSPI1LPEN, [28] M4XSPI1LPEN, [27] M7XSPI2EN, [26] M4XSPI2EN, [25] M7XSPI2LPEN, [24] M4XSPI2LPEN, [23] M7FEMCEN, [22] M4FEMCEN, [21] M7FEMCLPEN, [20] M4FEMCLPEN, [19] M7SDRAMEN, [18] M4SDRAMEN, [17] M7SDRAMLPEN, [16] M4SDRAMLPEN, [3] M7DSIULPSEN, [2] M4DSIULPSEN, [1] M7DSIULPSLPEN, [0] M4DSIULPSLPEN
0x150 RCC_AXIRST1 — nan
  [28] JPEGDRST, [20] JPEGERST, [16] DMAMUX2RST, [12] MDMARST, [9] SDMMC1RST, [8] SDHOST1RST, [4] ECCM1RST, [0] OTPCRST
0x154 RCC_AXIRST2 — nan
  [29] DSICFGRST, [28] DSIRST, [24] LCDCRST, [16] DVP1RST, [8] DVP2RST, [0] WWDG1RST
0x158 RCC_AXIRST3 — nan
  [0] GPURST
0x15C RCC_AXIRST4 — nan
  [28] XSPI1RST, [24] XSPI2RST, [21] FEMCCFGRST, [20] FEMCRST, [16] SDRAMRST
0x160 RCC_CFG2 reset 0x55ACCCCC — nan
  [30] M4CAHIEN, [28] M4CAHIPCLKEN, [26] M4CAHDEN, [24] M4CAHDPCLKEN, [23] M7MMUEN, [22] M7MMULPEN, [21] M4MMUEN, [20] M4MMULPEN, [19] M7SRAMBKPEN, [18] M4SRAMBKPEN, [17] M7SRAMBKPLPEN, [16] M4SRAMBKPLPEN, [19-4n] M7SRAM{n}EN (n=1..4), [18-4n] M4SRAM{n}EN (n=1..4), [17-4n] M7SRAM{n}LPEN (n=1..4), [16-4n] M4SRAM{n}LPEN (n=1..4)
0x164 RCC_CFG3 reset 0x44 — nan
  [31:28] MCO1SEL, [27:24] MCO1DIV, [23:20] MCO2SEL, [19:16] MCO2DIV, [15:14] I2SSEL, [13:12] PERSW, [7:4] M7STCLKDIV, [3:0] M4STCLKDIV
0x168 RCC_CFG4 reset 0xFFFFFDFE — nan
  [31] AHB1CLKEN, [30] AHB2CLKEN, [29] AHB3CLKEN, [27] AHB5CLKEN, [26] AHB6CLKEN, [23] AXICLKEN, [22] APB1CLKEN, [21] APB2CLKEN, [20] APB5CLKEN, [19] APB6CLKEN, [18] AHB9CLKEN, [17] AXIMM7GCLKEN, [16] AXIMM4GCLKEN, [15] HSICGEN, [14] HSIKERCGEN, [13] HSECGEN, [12] HSEKERCGEN, [11] MSICGEN, [10] MSIKERCGEN, [8] AXIMM7CLKEN, [7] AXIGCLKEN, [6] AXIMM4CLKEN, [5] DCMUM7CLKEN, [4] DCMUM4CLKEN, [3] AHBM1CLKEN, [2] AHBM2CLKEN, [1] AHBM3CLKEN, [0] DCMURST
0x16C RCC_SRCCTRL2 reset 0xF00 — nan
  [30] BORF, [29] HSICALEF, [28] MSICALEF, [17] M7HYPSEL, [16] AXIHYPSEL, [12:8] MSICAL ro, [4:0] MSITRIM
0x170 RCC_CFG5 reset 0x2C10000 — nan
  [29:24] RTCHSEDIV, [23] M7SRAM5EN, [22] M4SRAM5EN, [21] M7SRAM5LPEN, [20] M4SRAM5LPEN, [16] DCDCLKEN, [13] TRNGEN, [12] TRNGSEL, [11:8] TRNGDIV, [7:4] DSIHSEDIV, [3:0] RTCHSIDIV
0x174 RCC_M4RSTREL — nan
  [0] EN
0x178 RCC_AXIDIV2 — nan
  [23:20] DSIAXIPPIDIV, [19:16] DSIREFULPSDIV, [11:8] SDRAMMEMDIV, [7:4] FEMCM1AXIDIV, [3:0] FEMCM0AXIDIV
0x17C RCC_AXISEL2 — nan
  [10:8] SDRAMMEMSEL, [6:4] FEMCM1SEL, [2:0] FEMCM0SEL
0x18C RCC_SHRPLLCTRL1 reset 0x19030009 — nan
  [29:28] SHRPLLSRC, [20] SHRPLLPHLK ro, [19] SHRPLLLDOEN, [18] SHRPLLEN, [17] SHRPLLRST, [16] SHRPLLPD, [11:0] SHRPLLBWAJ
0x190 RCC_SHRPLLCTRL2 reset 0x4E200 — nan
  [31:26] SHRPLLCLKR, [25:0] SHRPLLCLKF
0x194 RCC_AHB1DIV2 reset 0x20202 — nan
  [21:16] ADC3SYSDIV, [13:8] ADC2SYSDIV, [5:0] ADC1SYSDIV
0x198 RCC_LSERDDL reset 0xFFF — nan
  [31:0] DELAY
0x19C RCC_MSIRDDL reset 0xF — nan
  [31:0] DELAY
0x1A0 RCC_HSERDDL reset 0x23280 — nan
  [31:0] DELAY
0x1A4 RCC_PLLSFTLK reset 0x20 — nan
  [28:25] SDRAMDLSEL, [24] SDRAMDLEN, [5] SHRTIMAFERST, [3] SHRPLLSFTLK, [2] PLL3SFTLK, [1] PLL2SFTLK, [0] PLL1SFTLK
0x1A8 RCC_RDCTRL1 — nan
  [29] LPTIM2FLTEN, [28] LPTIM2FLTSEL, [n+23] LPTIM2COMP{n}EN (n=1..4), [20:16] LPTIM2FLTDFC, [13] LPTIM1FLTEN, [12] LPTIM1FLTSEL, [n+7] LPTIM1COMP{n}EN (n=1..4), [4:0] LPTIM1FLTDFC
0x1AC RCC_RDCTRL2 — nan
  [29] LPTIM4FLTEN, [28] LPTIM4FLTSEL, [n+23] LPTIM4COMP{n}EN (n=1..4), [20:16] LPTIM4FLTDFC, [13] LPTIM3FLTEN, [12] LPTIM3FLTSEL, [n+7] LPTIM3COMP{n}EN (n=1..4), [4:0] LPTIM3FLTDFC
0x1B0 RCC_RDCTRL3 — nan
  [13] LPTIM5FLTEN, [12] LPTIM5FLTSEL, [n+7] LPTIM5COMP{n}EN (n=1..4), [4:0] LPTIM5FLTDFC
0x1B4 RCC_AHB2EN2 — nan
  [23] M7DAC56EN, [22] M4DAC56EN, [21] M7DAC56LPEN, [20] M4DAC56LPEN, [19] M7DAC34EN, [18] M4DAC34EN, [17] M7DAC34LPEN, [16] M4DAC34LPEN, [11] M7ETH1TXEN, [10] M4ETH1TXEN, [9] M7ETH1TXLPEN, [8] M4ETH1TXLPEN, [7] M7ETH1RXEN, [6] M4ETH1RXEN, [5] M7ETH1RXLPEN, [4] M4ETH1RXLPEN, [3] M7ETH1MACEN, [2] M4ETH1MACEN, [1] M7ETH1MACLPEN, [0] M4ETH1MACLPEN
0x1B8 RCC_AHB9DIV1 — nan
  [3:0] ESCSYSDIV
0x1BC RCC_AHB9SEL1 — nan
  [2:0] ESCKERSEL
0x1C0 RCC_AHB9EN1 — nan
  [3] M7ESCEN, [2] M4ESCEN, [1] M7ESCLPEN, [0] M4ESCLPEN
0x1C4 RCC_AHB9RST1 — nan
  [0] ESCRST
0x1C8 RCC_HSEOS reset 0x29400300 — nan
  [31:24] HSEMAXPDTHR, [23:16] HSEMINNDTHR, [15:8] HSEOSTHR, [6] HSEMAXPDF, [5] HSEMINNDF, [4] HSEOSF, [2] HSEMAXPDEN, [1] HSEMINNDEN, [0] HSEOSEN
0x1CC RCC_LSEOS reset 0x5 — nan
  [25] LSECALCNTEN, [24] LSECALCNTF ro, [23:16] LSECALCNT ro, [9] LSEOSF ro, [8] LSEOSEN, [7:0] LSEOSTHR
0x1D0 RCC_HSECAL — nan
  [17] HSECALCNTEN, [16] HSECALCNTF ro, [15:0] HSECALCNT ro
0x1D4 RCC_CLKINT3 — nan
  [18] PLL1LKFIE, [17] PLL1LKFIF ro, [16] PLL1LKFIC wo, [14] PLL2LKFIE, [13] PLL2LKFIF ro, [12] PLL2LKFIC wo, [10] PLL3LKFIE, [9] PLL3LKFIF ro, [8] PLL3LKFIC wo, [6] SHRPLLLKFIE, [5] SHRPLLLKFIF ro, [4] SHRPLLLKFIC wo, [2] LSIFIE, [1] LSIFIF ro, [0] LSIFIC wo
0x1D8 RCC_PLLFD — nan
  [11] SHRPLLGF ro, [10] PLL3GF ro, [9] PLL2GF ro, [8] PLL1GF ro, [7] SHRPLLFF ro, [6] PLL3FF ro, [5] PLL2FF ro, [4] PLL1FF ro, [3] SHRPLLFEN, [2] PLL3FEN, [1] PLL2FEN, [0] PLL1FEN
0x1DC RCC_SRCCTRL3 reset 0x1600000 — nan
  [24:16] HSICAL ro, [8:0] HSITRIM
0x1E0 RCC_LSICSSDL reset 0xC8 — nan
  [31:0] DELAY
